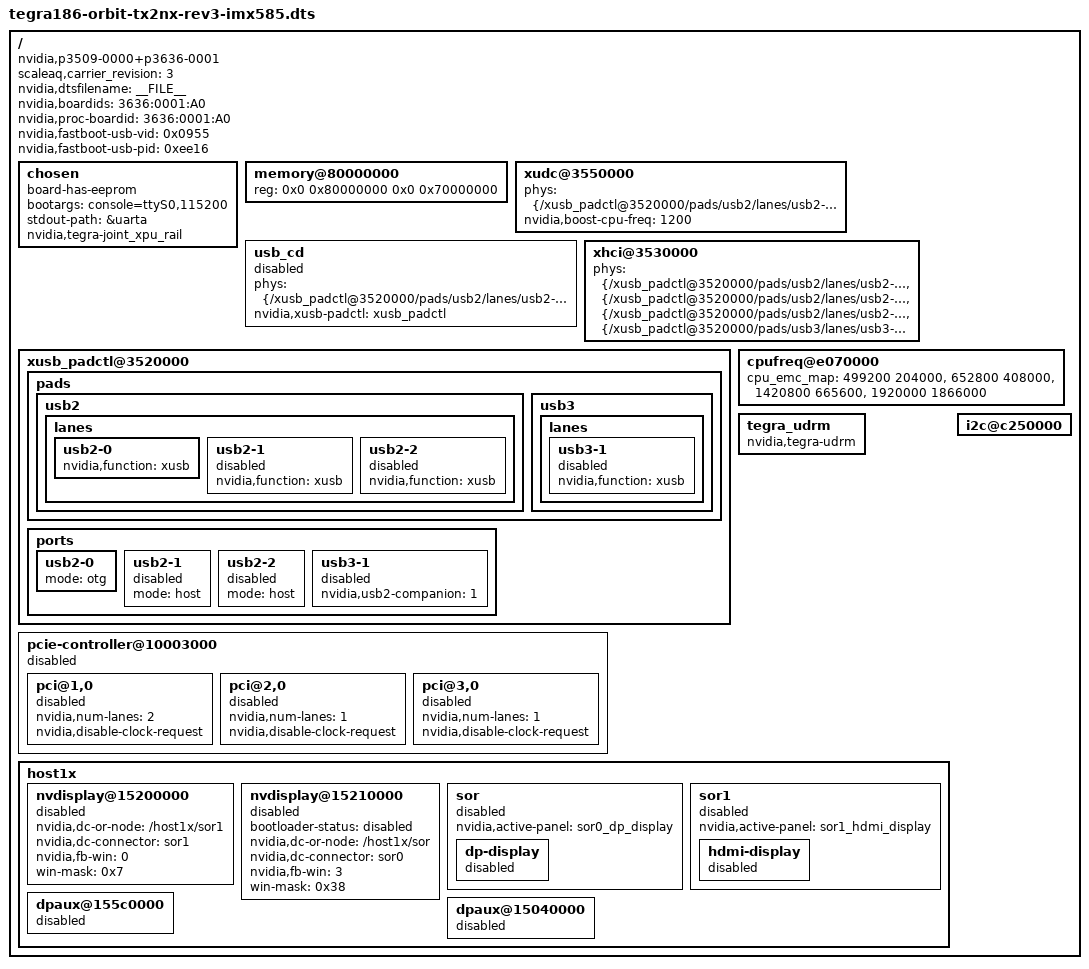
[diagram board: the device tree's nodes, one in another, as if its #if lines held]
/*
 * tegra186-p3636-0001-p3509-0000-a01.dts : Lanai A00 Board
 *
 * Copyright (c) 2020, NVIDIA CORPORATION. All rights reserved.
 *
 * This program is free software; you can redistribute it and/or modify
 * it under the terms of the GNU General Public License as published by
 * the Free Software Foundation; version 2 of the License.
 *
 * This program is distributed in the hope that it will be useful, but WITHOUT
 * ANY WARRANTY; without even the implied warranty of MERCHANTABILITY or
 * FITNESS FOR A PARTICULAR PURPOSE.  See the GNU General Public License for
 * more details.
 */
#include "tegra186-scaleaq-common.dtsi"
#include "common/tegra186-p3509-0000-cvb.dtsi"
#include "common/tegra186-p3509-0000-a00-fixed-regulator.dtsi"
#include "common/tegra186-p3636-0001-a00-prod.dtsi"
/* #include "common/tegra18x-orbit_tx2nx_rev3-padvoltage-default.dtsi" */
/* #include "common/tegra18x-orbit_tx2nx_rev3-pinmux.dtsi" */
/* #include "common/tegra18x-orbit_tx2nx_rev3-gpio-default.dtsi" */
#include "common/tegra186-camera-imx585.dtsi"

/ {
	compatible = "nvidia,p3509-0000+p3636-0001", "nvidia,tegra186";
	scaleaq,carrier_revision = "3";

	nvidia,dtsfilename = __FILE__;
	nvidia,boardids = "3636:0001:A0";
	nvidia,proc-boardid = "3636:0001:A0";
	nvidia,fastboot-usb-vid = <0x0955>;
	nvidia,fastboot-usb-pid = <0xee16>;

	chosen {
		board-has-eeprom;
		bootargs ="console=ttyS0,115200";
		stdout-path = &uarta;
		nvidia,tegra-joint_xpu_rail;
	};

	memory@80000000 {
		device_type = "memory";
		reg = <0x0 0x80000000 0x0 0x70000000>;
	};

	xudc@3550000 {
		status = "okay";
		phys = <&{/xusb_padctl@3520000/pads/usb2/lanes/usb2-0}>;
		phy-names = "usb2";
		nvidia,boost-cpu-freq = <1200>;
	};

	usb_cd {
		status = "disabled";
		phys = <&{/xusb_padctl@3520000/pads/usb2/lanes/usb2-0}>;
		phy-names = "otg-phy";
		nvidia,xusb-padctl = <&xusb_padctl>;
	};

	xhci@3530000 {
		status = "okay";
		phys = <&{/xusb_padctl@3520000/pads/usb2/lanes/usb2-0}>,
			<&{/xusb_padctl@3520000/pads/usb2/lanes/usb2-1}>,
			<&{/xusb_padctl@3520000/pads/usb2/lanes/usb2-2}>,
			<&{/xusb_padctl@3520000/pads/usb3/lanes/usb3-1}>;
		phy-names = "usb2-0", "usb2-1", "usb2-2", "usb3-1";
	};

	xusb_padctl@3520000 {
		status = "okay";

		pads {
			usb2 {
				lanes {
					usb2-0 {
						nvidia,function = "xusb";
						status = "okay";
					};
					usb2-1 {
						nvidia,function = "xusb";
						status = "disabled";
					};
					usb2-2 {
						nvidia,function = "xusb";
						status = "disabled";
					};
				};
			};
			usb3 {
				lanes {
					usb3-1 {
						nvidia,function = "xusb";
						status = "disabled";
					};
				};
			};
		};

		ports {
			usb2-0 {
				status = "okay";
				mode = "otg";
			};
			usb2-1 {
				status = "disabled";
				mode = "host";
			};
			usb2-2 {
				status = "disabled";
				mode = "host";
			};
			usb3-1 {
				nvidia,usb2-companion = <1>;
				status = "disabled";
			};
		};
	};

	pcie-controller@10003000 {
		status = "disabled";
		pci@1,0 {
			nvidia,num-lanes = <2>;
			nvidia,disable-clock-request;
			status = "disabled";
		};
		pci@2,0 {
			nvidia,num-lanes = <1>;
			nvidia,disable-clock-request;
			status = "disabled";
		};
		pci@3,0 {
			nvidia,num-lanes = <1>;
			nvidia,disable-clock-request;
			status = "disabled";
		};
	};

	cpufreq@e070000 {
		cpu_emc_map =
			< 499200  204000>,
			< 652800  408000>,
			<1420800  665600>,
			<1920000 1866000>;
	};

	tegra_udrm: tegra_udrm {
		compatible = "nvidia,tegra-udrm";
	};

	host1x {
		nvdisplay@15200000 {
			status = "disabled";
			nvidia,dc-or-node = "/host1x/sor1";
			nvidia,dc-connector = <&sor1>;
			nvidia,fb-win = <0>;
			win-mask = <0x7>;
		};
		nvdisplay@15210000 {
			status = "disabled";
			bootloader-status = "disabled";
			nvidia,dc-or-node = "/host1x/sor";
			nvidia,dc-connector = <&sor0>;
			nvidia,fb-win = <3>;
			win-mask = <0x38>;
		};
		sor {
			status = "disabled";
			nvidia,active-panel = <&sor0_dp_display>;
			dp-display {
				status = "disabled";
			};
		};
		sor1 {
			status = "disabled";
			nvidia,active-panel = <&sor1_hdmi_display>;
			hdmi-display {
				status = "disabled";
			};
		};
		dpaux@155c0000 {
			status = "disabled";
		};
		dpaux@15040000 {
			status = "disabled";
		};
	};

	i2c@c250000 {
		status = "okay";
	};


};
#if LINUX_VERSION >= 414
#include <tegra186-linux-4.14.dtsi>
#endif
